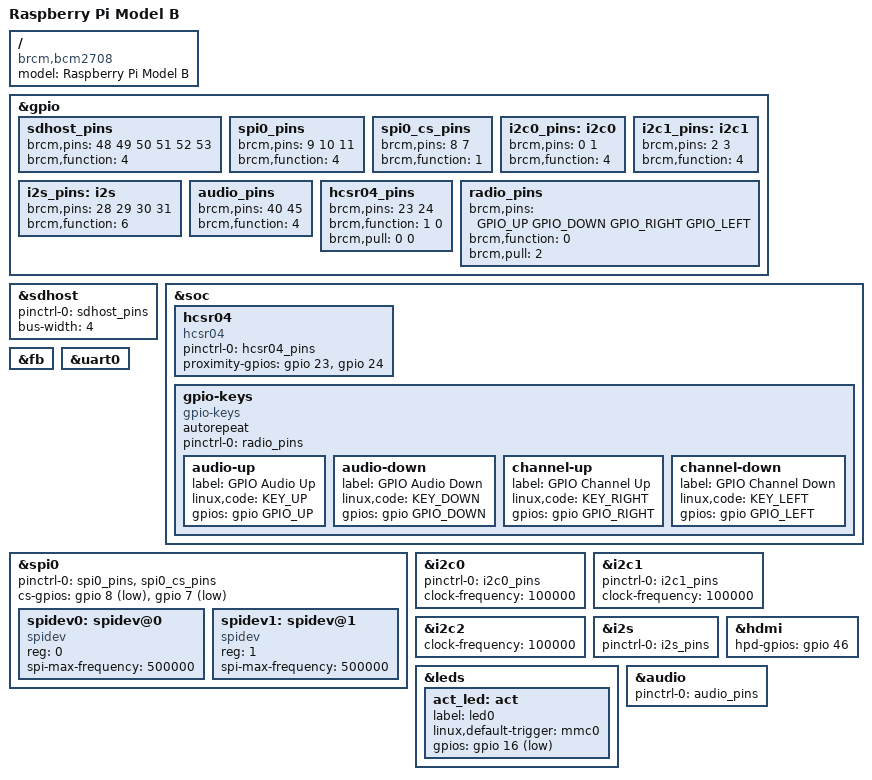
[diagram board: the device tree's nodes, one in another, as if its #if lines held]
/dts-v1/;

#define KEY_UP       103
#define KEY_DOWN     104
#define KEY_RIGHT    106
#define KEY_LEFT     105

#define GPIO_UP        4
#define GPIO_DOWN      17
#define GPIO_RIGHT     27
#define GPIO_LEFT      22

//#define HAS_PROXIMITY_SENSOR
#define HAS_RADIO_BUTTONS

#include "bcm2708.dtsi"

/ {
	compatible = "brcm,bcm2708";
	model = "Raspberry Pi Model B";
};

&gpio {
	sdhost_pins: sdhost_pins {
		brcm,pins = <48 49 50 51 52 53>;
		brcm,function = <4>; /* alt0 */
	};

	spi0_pins: spi0_pins {
		brcm,pins = <9 10 11>;
		brcm,function = <4>; /* alt0 */
	};

	spi0_cs_pins: spi0_cs_pins {
		brcm,pins = <8 7>;
		brcm,function = <1>; /* output */
	};

	i2c0_pins: i2c0 {
		brcm,pins = <0 1>;
		brcm,function = <4>;
	};

	i2c1_pins: i2c1 {
		brcm,pins = <2 3>;
		brcm,function = <4>;
	};

	i2s_pins: i2s {
		brcm,pins = <28 29 30 31>;
		brcm,function = <6>; /* alt2 */
	};

	audio_pins: audio_pins {
		brcm,pins = <40 45>;
		brcm,function = <4>;
	};
	
#ifdef HAS_PROXIMITY_SENSOR	
	hcsr04_pins: hcsr04_pins {
	       brcm,pins =    <23 24>;   // trigger, echo
	       brcm,function = <1 0>;    // out,  in
	       brcm,pull =     <0 0>;      // none
	};
#endif 

#ifdef HAS_RADIO_BUTTONS
	radio_pins: radio_pins {
	       brcm,pins =    <GPIO_UP GPIO_DOWN GPIO_RIGHT GPIO_LEFT>;
	       brcm,function = <0>;    // in
	       brcm,pull =     <2>;    // pull-up
	};
#endif

};

&sdhost {
	pinctrl-names = "default";
	pinctrl-0 = <&sdhost_pins>;
	bus-width = <4>;
	status = "okay";
};

&soc {
#ifdef HAS_PROXIMITY_SENSOR
       hcsr04: hcsr04 {
               compatible = "hcsr04";
               pinctrl-names = "default";
               pinctrl-0 = <&hcsr04_pins>;
               // see Documentation/gpio/board.txt
               proximity-gpios = <&gpio 23 0>, // trigger
                                 <&gpio 24 0>; // echo
               status="okay";
       };
#endif

#ifdef HAS_RADIO_BUTTONS
		gpio-keys {
			compatible = "gpio-keys";
			autorepeat;

           pinctrl-names = "default";
           pinctrl-0 = <&radio_pins>;

			audio-up {
				label = "GPIO Audio Up";
				linux,code = <KEY_UP>;
				gpios = <&gpio GPIO_UP 0>;
			};

			audio-down {
				label = "GPIO Audio Down";
				linux,code = <KEY_DOWN>;
				gpios = <&gpio GPIO_DOWN 0>;
			};

			channel-up {
				label = "GPIO Channel Up";
				linux,code = <KEY_RIGHT>;
				gpios = <&gpio GPIO_RIGHT 0>;
			};

			channel-down {
				label = "GPIO Channel Down";
				linux,code = <KEY_LEFT>;
				gpios = <&gpio GPIO_LEFT 0>;
			};

		};
#endif

};

&fb {
	status = "okay";
};

&uart0 {
	status = "okay";
};

&spi0 {
	pinctrl-names = "default";
	pinctrl-0 = <&spi0_pins &spi0_cs_pins>;
	cs-gpios = <&gpio 8 1>, <&gpio 7 1>;

	spidev0: spidev@0{
		compatible = "spidev";
		reg = <0>;	/* CE0 */
		#address-cells = <1>;
		#size-cells = <0>;
		spi-max-frequency = <500000>;
	};

	spidev1: spidev@1{
		compatible = "spidev";
		reg = <1>;	/* CE1 */
		#address-cells = <1>;
		#size-cells = <0>;
		spi-max-frequency = <500000>;
	};
};

&i2c0 {
	pinctrl-names = "default";
	pinctrl-0 = <&i2c0_pins>;
	clock-frequency = <100000>;
};

&i2c1 {
	pinctrl-names = "default";
	pinctrl-0 = <&i2c1_pins>;
	clock-frequency = <100000>;
};

&i2c2 {
	clock-frequency = <100000>;
};

&i2s {
	pinctrl-names = "default";
	pinctrl-0 = <&i2s_pins>;
};

&leds {
	act_led: act {
		label = "led0";
		linux,default-trigger = "mmc0";
		gpios = <&gpio 16 1>;
	};
};

&hdmi {
	hpd-gpios = <&gpio 46 GPIO_ACTIVE_HIGH>;
};

&audio {
	pinctrl-names = "default";
	pinctrl-0 = <&audio_pins>;
};

/ {
	__overrides__ {
		uart0 = <&uart0>,"status";
		uart1 = <&uart1>,"status";
		i2s = <&i2s>,"status";
		spi = <&spi0>,"status";
		i2c0 = <&i2c0>,"status";
		i2c1 = <&i2c1>,"status";
		i2c2_iknowwhatimdoing = <&i2c2>,"status";
		i2c0_baudrate = <&i2c0>,"clock-frequency:0";
		i2c1_baudrate = <&i2c1>,"clock-frequency:0";
		i2c2_baudrate = <&i2c2>,"clock-frequency:0";

		act_led_gpio = <&act_led>,"gpios:4";
		act_led_activelow = <&act_led>,"gpios:8";
		act_led_trigger = <&act_led>,"linux,default-trigger";

		audio = <&audio>,"status";
		watchdog = <&watchdog>,"status";
		random = <&random>,"status";
		sd_overclock = <&sdhost>,"brcm,overclock-50:0";
		sd_force_pio = <&sdhost>,"brcm,force-pio?";
		sd_pio_limit = <&sdhost>,"brcm,pio-limit:0";
		sd_debug     = <&sdhost>,"brcm,debug";
	};
};
